VERSION ""

NS_ :

BS_:

BU_: Car1516_ATCC_Front

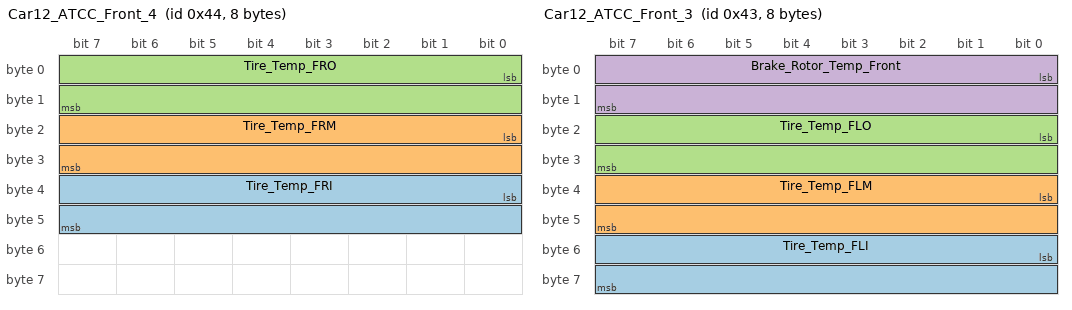
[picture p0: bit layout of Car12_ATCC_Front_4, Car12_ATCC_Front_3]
BO_ 68 Car12_ATCC_Front_4: 8 Car1516_ATCC_Front
 SG_ Tire_Temp_FRI : 32|16@1- (0.0048,16.206) [-141.0804|173.4876] "°F" Vector__XXX
 SG_ Tire_Temp_FRM : 16|16@1- (0.0048,16.206) [-141.0804|173.4876] "°F" Vector__XXX
 SG_ Tire_Temp_FRO : 0|16@1- (0.0048,16.206) [-141.0804|173.4876] "°F" Vector__XXX

BO_ 67 Car12_ATCC_Front_3: 8 Car1516_ATCC_Front
 SG_ Tire_Temp_FLI : 48|16@1- (0.0048,16.206) [-141.0804|173.4876] "°F" Vector__XXX
 SG_ Tire_Temp_FLM : 32|16@1- (0.0048,16.206) [-141.0804|173.4876] "°F" Vector__XXX
 SG_ Tire_Temp_FLO : 16|16@1- (0.0048,16.206) [-141.0804|173.4876] "°F" Vector__XXX
 SG_ Brake_Rotor_Temp_Front : 0|16@1- (0.1,0) [-3276.8|3276.7] "°C" Vector__XXX

BO_ 66 Car12_ATCC_Front_2: 8 Car1516_ATCC_Front
 SG_ Brake_Press_F : 16|16@1- (0.1,-600) [-3876.8|2676.7] "psi" Vector__XXX
 SG_ Brake_Press_R : 0|16@1- (0.1,-600) [-3876.8|2676.7] "psi" Vector__XXX

BO_ 65 Car12_ATCC_Front_1: 8 Car1516_ATCC_Front

BO_ 64 Car12_ATCC_Front_0: 8 Car1516_ATCC_Front
 SG_ Linear_Pot_FR : 16|16@1- (-0.0015,75) [16.0176|133.9806] "cm" Vector__XXX
 SG_ Linear_Pot_FL : 0|16@1- (-0.0015,75) [16.0176|133.9806] "cm" Vector__XXX
